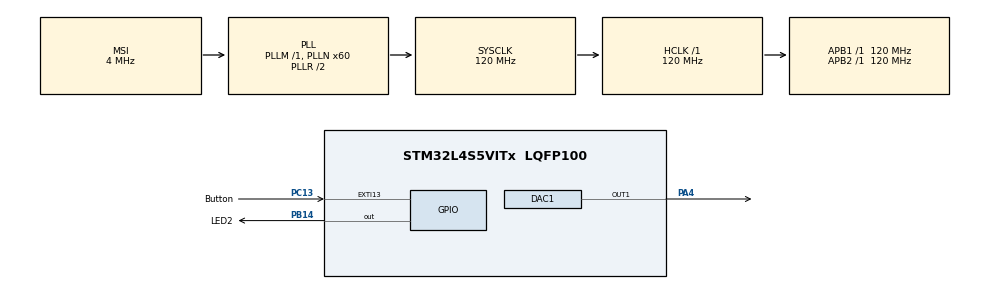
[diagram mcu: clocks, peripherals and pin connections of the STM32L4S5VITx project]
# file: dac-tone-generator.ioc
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DAC1.DAC_OutputBuffer-DAC_OUT1=DAC_OUTPUTBUFFER_ENABLE
DAC1.DAC_Trigger-DAC_OUT1=DAC_TRIGGER_T2_TRGO
Dma.DAC1_CH1.0.Direction=DMA_MEMORY_TO_PERIPH
Dma.DAC1_CH1.0.EventEnable=DISABLE
Dma.DAC1_CH1.0.Instance=DMA1_Channel1
Dma.DAC1_CH1.0.MemDataAlignment=DMA_MDATAALIGN_BYTE
Dma.DAC1_CH1.0.MemInc=DMA_MINC_ENABLE
Dma.DAC1_CH1.0.Mode=DMA_CIRCULAR
Dma.DAC1_CH1.0.PeriphDataAlignment=DMA_PDATAALIGN_HALFWORD
Dma.DAC1_CH1.0.PeriphInc=DMA_PINC_DISABLE
Dma.DAC1_CH1.0.Polarity=HAL_DMAMUX_REQUEST_GEN_RISING
Dma.DAC1_CH1.0.Priority=DMA_PRIORITY_LOW
Dma.DAC1_CH1.0.RequestNumber=1
Dma.DAC1_CH1.0.SignalID=NONE
Dma.DAC1_CH1.0.SyncEnable=DISABLE
Dma.DAC1_CH1.0.SyncPolarity=HAL_DMAMUX_SYNC_NO_EVENT
Dma.DAC1_CH1.0.SyncRequestNumber=1
Dma.DAC1_CH1.0.SyncSignalID=NONE
Dma.Request0=DAC1_CH1
Mcu.Family=STM32L4
Mcu.Name=STM32L4S5VITx
Mcu.Package=LQFP100
NVIC.DMA1_Channel1_IRQn=true\:0\:0\:false\:false\:true\:false\:true\:true
NVIC.EXTI15_10_IRQn=true\:0\:0\:false\:false\:true\:true\:true\:true
NVIC.PriorityGroup=NVIC_PRIORITYGROUP_4
NVIC.TIM2_IRQn=true\:0\:0\:false\:false\:true\:true\:true\:true
PA4.Signal=COMP_DAC11_group
PB14.GPIO_Label=LED2
PB14.Signal=GPIO_Output
PC13.GPIO_Label=Button
PC13.Signal=GPXTI13
ProjectManager.HeapSize=0x200
ProjectManager.StackSize=0x400
ProjectManager.TargetToolchain=STM32CubeIDE
RCC.ADCFreq_Value=48000000
RCC.AHBFreq_Value=120000000
RCC.APB1Freq_Value=120000000
RCC.APB1TimFreq_Value=120000000
RCC.APB2Freq_Value=120000000
RCC.APB2TimFreq_Value=120000000
RCC.CortexFreq_Value=120000000
RCC.HCLKFreq_Value=120000000
RCC.HSE_VALUE=8000000
RCC.HSI48_VALUE=48000000
RCC.HSI_VALUE=16000000
RCC.LSE_VALUE=32768
RCC.MSI_VALUE=4000000
RCC.PLLN=60
RCC.PLLSAI1N=24
RCC.SYSCLKFreq_VALUE=120000000
RCC.SYSCLKSource=RCC_SYSCLKSOURCE_PLLCLK
RCC.USBFreq_Value=48000000
RCC.VCOOutputFreq_Value=240000000
SH.COMP_DAC11_group.0=DAC1_OUT1,DAC_OUT1
TIM2.AutoReloadPreload=TIM_AUTORELOAD_PRELOAD_ENABLE
TIM2.Period=3582
TIM2.TIM_MasterOutputTrigger=TIM_TRGO_UPDATE
VP_TIM2_VS_ClockSourceINT.Mode=Internal
board=B-L4S5I-IOT01A

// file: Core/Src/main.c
/* USER CODE BEGIN Header */
/**
  ******************************************************************************
  * @file           : main.c
  * @brief          : Main program body
  ******************************************************************************
  * @attention
  *
  * Copyright (c) 2026 STMicroelectronics.
  * All rights reserved.
  *
  * This software is licensed under terms that can be found in the LICENSE file
  * in the root directory of this software component.
  * If no LICENSE file comes with this software, it is provided AS-IS.
  *
  ******************************************************************************
  */
/* USER CODE END Header */
#include "main.h"

/* USER CODE BEGIN Includes */
/* CMSIS-DSP, used for arm_sin_f32() and PI. This version of arm_math.h
   requires the core to be defined before it is included. */
#define ARM_MATH_CM4
#include "arm_math.h"
/* USER CODE END Includes */

/* USER CODE BEGIN PD */
/* 0: TIM2 interrupt writes each sample to the DAC (Part 2, timer step)
   1: TIM2 TRGO triggers the DAC and DMA feeds it from sine[] (DMA step) */
#define USE_DMA      1

#define SINE_N       32      /* samples per sine period */
#define NUM_TONES    3       /* C6, E6, G6 */
#define DEBOUNCE_MS  200U    /* button debounce window */
/* USER CODE END PD */

DAC_HandleTypeDef hdac1;
DMA_HandleTypeDef hdma_dac1_ch1;

TIM_HandleTypeDef htim2;

/* USER CODE BEGIN PV */
/* One full sine period, 8-bit DAC codes */
uint8_t sine[SINE_N];

/* Note frequencies in Hz: C6, E6, G6 */
static const float tone_hz[NUM_TONES] = { 1046.50f, 1318.51f, 1567.98f };

/* TIM2 auto-reload value for each note, set at startup.
   f_note = f_timer / ((ARR + 1) * SINE_N)  =>  ARR = f_timer / (SINE_N * f_note) - 1 */
uint32_t tone_arr[NUM_TONES];

/* Shared with interrupt handlers */
volatile uint32_t tone_index = 0;
volatile uint32_t sample_idx = 0;
volatile uint32_t last_press = 0;
/* USER CODE END PV */

void SystemClock_Config(void);
static void MX_GPIO_Init(void);
static void MX_DMA_Init(void);
static void MX_DAC1_Init(void);
static void MX_TIM2_Init(void);

int main(void)
{

  /* MCU Configuration--------------------------------------------------------*/

  /* Reset of all peripherals, Initializes the Flash interface and the Systick. */
  HAL_Init();

  /* Configure the system clock */
  SystemClock_Config();

  /* Initialize all configured peripherals */
  MX_GPIO_Init();
  MX_DMA_Init();
  MX_DAC1_Init();
  MX_TIM2_Init();
  /* USER CODE BEGIN 2 */
  /* Build the sine table. Centred at mid-scale (128) with an amplitude of 85,
     i.e. about 2/3 of the 8-bit range, to avoid clipping under the speaker load. */
  for (int i = 0; i < SINE_N; i++)
  {
    float s = arm_sin_f32(2.0f * PI * (float)i / (float)SINE_N);
    sine[i] = (uint8_t)(128.0f + 85.0f * s + 0.5f);
  }

  /* TIM2 runs on APB1. Timer clocks are doubled when the APB1 prescaler is not 1. */
  uint32_t f_timer = HAL_RCC_GetPCLK1Freq();
  if ((RCC->CFGR & RCC_CFGR_PPRE1) != RCC_CFGR_PPRE1_DIV1)
    f_timer *= 2U;

  /* At 120 MHz: 3582 (C6), 2844 (E6), 2391 (G6) */
  for (int k = 0; k < NUM_TONES; k++)
    tone_arr[k] = (uint32_t)((float)f_timer / ((float)SINE_N * tone_hz[k]) + 0.5f) - 1U;

  __HAL_TIM_SET_AUTORELOAD(&htim2, tone_arr[0]);

#if USE_DMA
  /* DMA must be added to DAC1 in CubeMX, otherwise there is no handle */
  if (hdac1.DMA_Handle1 == NULL)
    Error_Handler();

  /* Start the DAC/DMA before the timer so data is ready on the first trigger.
     The timer runs without its interrupt; its TRGO drives the DAC directly. */
  HAL_DAC_Start_DMA(&hdac1, DAC_CHANNEL_1, (uint32_t *)sine, SINE_N, DAC_ALIGN_8B_R);
  HAL_TIM_Base_Start(&htim2);
#else
  /* Samples are written in HAL_TIM_PeriodElapsedCallback */
  HAL_DAC_Start(&hdac1, DAC_CHANNEL_1);
  HAL_TIM_Base_Start_IT(&htim2);
#endif
  /* USER CODE END 2 */

  /* Infinite loop */
  while (1)
  {

    /* USER CODE BEGIN 3 */
    /* Nothing to do: output is driven by TIM2 (and DMA), the button by EXTI */
  }
  /* USER CODE END 3 */
}

void SystemClock_Config(void)
{
  RCC_OscInitTypeDef RCC_OscInitStruct = {0};
  RCC_ClkInitTypeDef RCC_ClkInitStruct = {0};

  /** Configure the main internal regulator output voltage
  */
  if (HAL_PWREx_ControlVoltageScaling(PWR_REGULATOR_VOLTAGE_SCALE1_BOOST) != HAL_OK)
  {
    Error_Handler();
  }

  /** Initializes the RCC Oscillators according to the specified parameters
  * in the RCC_OscInitTypeDef structure.
  */
  RCC_OscInitStruct.OscillatorType = RCC_OSCILLATORTYPE_MSI;
  RCC_OscInitStruct.MSIState = RCC_MSI_ON;
  RCC_OscInitStruct.MSICalibrationValue = 0;
  RCC_OscInitStruct.MSIClockRange = RCC_MSIRANGE_6;
  RCC_OscInitStruct.PLL.PLLState = RCC_PLL_ON;
  RCC_OscInitStruct.PLL.PLLSource = RCC_PLLSOURCE_MSI;
  RCC_OscInitStruct.PLL.PLLM = 1;
  RCC_OscInitStruct.PLL.PLLN = 60;
  RCC_OscInitStruct.PLL.PLLP = RCC_PLLP_DIV2;
  RCC_OscInitStruct.PLL.PLLQ = RCC_PLLQ_DIV2;
  RCC_OscInitStruct.PLL.PLLR = RCC_PLLR_DIV2;
  if (HAL_RCC_OscConfig(&RCC_OscInitStruct) != HAL_OK)
  {
    Error_Handler();
  }

  /** Initializes the CPU, AHB and APB buses clocks
  */
  RCC_ClkInitStruct.ClockType = RCC_CLOCKTYPE_HCLK|RCC_CLOCKTYPE_SYSCLK
                              |RCC_CLOCKTYPE_PCLK1|RCC_CLOCKTYPE_PCLK2;
  RCC_ClkInitStruct.SYSCLKSource = RCC_SYSCLKSOURCE_PLLCLK;
  RCC_ClkInitStruct.AHBCLKDivider = RCC_SYSCLK_DIV1;
  RCC_ClkInitStruct.APB1CLKDivider = RCC_HCLK_DIV1;
  RCC_ClkInitStruct.APB2CLKDivider = RCC_HCLK_DIV1;

  if (HAL_RCC_ClockConfig(&RCC_ClkInitStruct, FLASH_LATENCY_5) != HAL_OK)
  {
    Error_Handler();
  }
}

static void MX_DAC1_Init(void)
{

  DAC_ChannelConfTypeDef sConfig = {0};

  /** DAC Initialization
  */
  hdac1.Instance = DAC1;
  if (HAL_DAC_Init(&hdac1) != HAL_OK)
  {
    Error_Handler();
  }

  /** DAC channel OUT1 config
  */
  sConfig.DAC_SampleAndHold = DAC_SAMPLEANDHOLD_DISABLE;
  sConfig.DAC_Trigger = DAC_TRIGGER_T2_TRGO;
  sConfig.DAC_HighFrequency = DAC_HIGH_FREQUENCY_INTERFACE_MODE_ABOVE_80MHZ;
  sConfig.DAC_OutputBuffer = DAC_OUTPUTBUFFER_ENABLE;
  sConfig.DAC_ConnectOnChipPeripheral = DAC_CHIPCONNECT_DISABLE;
  sConfig.DAC_UserTrimming = DAC_TRIMMING_FACTORY;
  if (HAL_DAC_ConfigChannel(&hdac1, &sConfig, DAC_CHANNEL_1) != HAL_OK)
  {
    Error_Handler();
  }

}

static void MX_TIM2_Init(void)
{

  TIM_ClockConfigTypeDef sClockSourceConfig = {0};
  TIM_MasterConfigTypeDef sMasterConfig = {0};

  htim2.Instance = TIM2;
  htim2.Init.Prescaler = 0;
  htim2.Init.CounterMode = TIM_COUNTERMODE_UP;
  htim2.Init.Period = 3582;
  htim2.Init.ClockDivision = TIM_CLOCKDIVISION_DIV1;
  htim2.Init.AutoReloadPreload = TIM_AUTORELOAD_PRELOAD_ENABLE;
  if (HAL_TIM_Base_Init(&htim2) != HAL_OK)
  {
    Error_Handler();
  }
  sClockSourceConfig.ClockSource = TIM_CLOCKSOURCE_INTERNAL;
  if (HAL_TIM_ConfigClockSource(&htim2, &sClockSourceConfig) != HAL_OK)
  {
    Error_Handler();
  }
  sMasterConfig.MasterOutputTrigger = TIM_TRGO_UPDATE;
  sMasterConfig.MasterSlaveMode = TIM_MASTERSLAVEMODE_DISABLE;
  if (HAL_TIMEx_MasterConfigSynchronization(&htim2, &sMasterConfig) != HAL_OK)
  {
    Error_Handler();
  }

}

static void MX_DMA_Init(void)
{

  /* DMA controller clock enable */
  __HAL_RCC_DMAMUX1_CLK_ENABLE();
  __HAL_RCC_DMA1_CLK_ENABLE();

  /* DMA interrupt init */
  /* DMA1_Channel1_IRQn interrupt configuration */
  HAL_NVIC_SetPriority(DMA1_Channel1_IRQn, 0, 0);
  HAL_NVIC_EnableIRQ(DMA1_Channel1_IRQn);

}

static void MX_GPIO_Init(void)
{
  GPIO_InitTypeDef GPIO_InitStruct = {0};

  /* GPIO Ports Clock Enable */
  __HAL_RCC_GPIOC_CLK_ENABLE();
  __HAL_RCC_GPIOA_CLK_ENABLE();
  __HAL_RCC_GPIOB_CLK_ENABLE();

  /*Configure GPIO pin Output Level */
  HAL_GPIO_WritePin(LED2_GPIO_Port, LED2_Pin, GPIO_PIN_RESET);

  /*Configure GPIO pin : Button_Pin */
  GPIO_InitStruct.Pin = Button_Pin;
  GPIO_InitStruct.Mode = GPIO_MODE_IT_RISING;
  GPIO_InitStruct.Pull = GPIO_NOPULL;
  HAL_GPIO_Init(Button_GPIO_Port, &GPIO_InitStruct);

  /*Configure GPIO pin : LED2_Pin */
  GPIO_InitStruct.Pin = LED2_Pin;
  GPIO_InitStruct.Mode = GPIO_MODE_OUTPUT_PP;
  GPIO_InitStruct.Pull = GPIO_NOPULL;
  GPIO_InitStruct.Speed = GPIO_SPEED_FREQ_LOW;
  HAL_GPIO_Init(LED2_GPIO_Port, &GPIO_InitStruct);

  /* EXTI interrupt init*/
  HAL_NVIC_SetPriority(EXTI15_10_IRQn, 0, 0);
  HAL_NVIC_EnableIRQ(EXTI15_10_IRQn);

}

/* USER CODE BEGIN 4 */
/* Button (PC13, EXTI13): toggle LED2 and step to the next note.
   Overrides the weak HAL callback. */
void HAL_GPIO_EXTI_Callback(uint16_t GPIO_Pin)
{
  if (GPIO_Pin != Button_Pin)
    return;

  uint32_t now = HAL_GetTick();
  if (now - last_press < DEBOUNCE_MS)
    return;
  last_press = now;

  HAL_GPIO_TogglePin(LED2_GPIO_Port, LED2_Pin);

  /* Changing the timer period changes the sample rate, and therefore the pitch.
     ARR preload is enabled, so the new value applies from the next update event. */
  tone_index = (tone_index + 1U) % NUM_TONES;
  __HAL_TIM_SET_AUTORELOAD(&htim2, tone_arr[tone_index]);
}

#if !USE_DMA
/* TIM2 update: output the next sample. Not used in DMA mode. */
void HAL_TIM_PeriodElapsedCallback(TIM_HandleTypeDef *htim)
{
  if (htim->Instance != TIM2)
    return;

  HAL_DAC_SetValue(&hdac1, DAC_CHANNEL_1, DAC_ALIGN_8B_R, sine[sample_idx]);
  sample_idx = (sample_idx + 1U) % SINE_N;
}
#endif
/* USER CODE END 4 */

void Error_Handler(void)
{
  __disable_irq();
  while (1)
  {
  }
}
